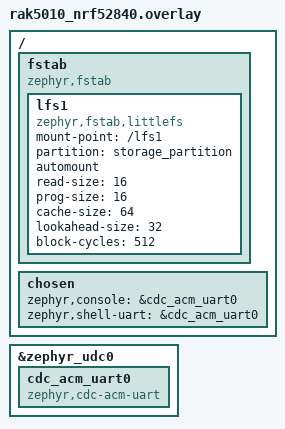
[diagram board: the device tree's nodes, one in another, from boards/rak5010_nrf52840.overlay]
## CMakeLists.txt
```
# SPDX-License-Identifier: Apache-2.0

cmake_minimum_required(VERSION 3.20.0)

find_package(Zephyr REQUIRED HINTS $ENV{ZEPHYR_BASE})
project(cert_rotation)

target_sources(app PRIVATE src/main.c)

add_custom_command(
    OUTPUT ${ZEPHYR_BINARY_DIR}/lfs.hex
    COMMAND ${PYTHON_EXECUTABLE}
      ${CMAKE_CURRENT_SOURCE_DIR}/generate-lfs-image.py
      --build-dir ${APPLICATION_BINARY_DIR}
)

add_custom_target(
    lfs ALL
    DEPENDS ${ZEPHYR_BINARY_DIR}/lfs.hex
)
```

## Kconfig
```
# Copyright (c) 2021 Golioth, Inc.
# SPDX-License-Identifier: Apache-2.0

source "${ZEPHYR_GOLIOTH_FIRMWARE_SDK_MODULE_DIR}/examples/zephyr/common/Kconfig.defconfig"

source "Kconfig.zephyr"
```

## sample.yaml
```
sample:
  description: Perform certificate rotation
  name: certificate_rotation
common:
  tags:
    - golioth
    - socket
    - goliothd
tests:
  sample.golioth.certificate_rotation:
    build_only: true
    tags:
      - golioth
      - socket
      - goliothd
    timeout: 180
    extra_configs:
      - CONFIG_GOLIOTH_SAMPLE_TWISTER_TEST=y
      - arch:posix:CONFIG_NATIVE_UART_0_ON_STDINOUT=y
    platform_allow:
      - frdm_rw612
      - native_sim
      - native_sim/native/64
      - nrf9160dk/nrf9160/ns
      - nucleo_h563zi/stm32h563xx
  sample.golioth.certificate_rotation.psa_crypto:
    build_only: true
    tags:
      - golioth
      - socket
      - goliothd
    timeout: 180
    extra_configs:
      - CONFIG_MBEDTLS_PSA_CRYPTO_C=y
      - CONFIG_GOLIOTH_SAMPLE_TWISTER_TEST=y
      - arch:posix:CONFIG_NATIVE_UART_0_ON_STDINOUT=y
      - arch:posix:CONFIG_MCUMGR_TRANSPORT_UDP_PORT=1347
    platform_allow:
      - frdm_rw612
      - native_sim
      - native_sim/native/64
      - nrf9160dk/nrf9160/ns
      - nucleo_h563zi/stm32h563xx
```

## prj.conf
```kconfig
# Application
CONFIG_GOLIOTH_SAMPLE_COMMON=y
CONFIG_LOG_BACKEND_GOLIOTH=y

# Golioth Firmware SDK with all dependencies
CONFIG_GOLIOTH_FIRMWARE_SDK=y

# Enable flash operations
CONFIG_FLASH=y
CONFIG_FLASH_MAP=y

# Enable the LittleFS file system
CONFIG_FILE_SYSTEM=y
# init before wifi credentials
CONFIG_FILE_SYSTEM_INIT_PRIORITY=89
CONFIG_FILE_SYSTEM_LITTLEFS=y
CONFIG_FILE_SYSTEM_SHELL=y
CONFIG_HEAP_MEM_POOL_SIZE=4096

# Add 256 bytes to accommodate upload command (lfs_stat overflows)
CONFIG_SYSTEM_WORKQUEUE_STACK_SIZE=2304

# Enable mcumgr
CONFIG_ZCBOR=y
CONFIG_MCUMGR=y

# Enable console with mcumgr pass through
CONFIG_CONSOLE=y
CONFIG_UART_CONSOLE=y
CONFIG_UART_CONSOLE_MCUMGR=y

# Enable the shell mcumgr transport. This allows SMP messages to pass
# through the shell to the mgmt subsystem.
CONFIG_SHELL=y
CONFIG_SHELL_BACKEND_SERIAL=y
CONFIG_BASE64=y
CONFIG_MCUMGR_TRANSPORT_SHELL=y

# Enable file system commands
CONFIG_MCUMGR_GRP_FS=y

# Enable shell commands over SMP
CONFIG_SHELL_BACKEND_DUMMY=y
CONFIG_MCUMGR_GRP_SHELL=y

# Some mgmt command handlers require a large stack.
CONFIG_MAIN_STACK_SIZE=2048

# Enable certificate authentication.
CONFIG_GOLIOTH_AUTH_METHOD_CERT=y

# Enable `log halt` and `log go` commands
CONFIG_LOG_CMDS=y

# If runtime-settings are enabled, use the file storage-backend
CONFIG_SETTINGS_FILE=y
CONFIG_SETTINGS_FILE_PATH="/lfs1/settings"

# Enable Golioth PKI Service:
CONFIG_GOLIOTH_PKI=y

# Enable MbedTLS Certificate Sigining Request writing:
CONFIG_MBEDTLS_X509_CSR_WRITE_C=y
CONFIG_MBEDTLS_PK_WRITE_C=y
CONFIG_MBEDTLS_PSA_CRYPTO_C=y
```

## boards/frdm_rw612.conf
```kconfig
CONFIG_GOLIOTH_SAMPLE_DHCP_BIND=y
CONFIG_NET_DHCPV4=y
CONFIG_BUILD_OUTPUT_HEX=y

# Ethernet autonegotiation can take longer than the default 4 s
CONFIG_PHY_AUTONEG_TIMEOUT_MS=10000

# Needed for certificate auth
CONFIG_NET_BUF_DATA_SIZE=512
CONFIG_NET_SOCKETS_CONNECT_TIMEOUT=6000
```

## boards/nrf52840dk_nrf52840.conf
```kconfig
# MCU Manager
CONFIG_MCUBOOT_BOOTUTIL_LIB=y
CONFIG_MCUMGR_MGMT_NOTIFICATION_HOOKS=y
CONFIG_MCUMGR_GRP_FS_FILE_ACCESS_HOOK=y

# Allow reboot from shell after loading certificates
CONFIG_REBOOT=y

CONFIG_NET_BUF_DATA_SIZE=256
CONFIG_NET_PKT_TX_COUNT=10

# DTLS handshake timeout
CONFIG_NET_SOCKETS_CONNECT_TIMEOUT=30000
```

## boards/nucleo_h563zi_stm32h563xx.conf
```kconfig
CONFIG_GOLIOTH_SAMPLE_DHCP_BIND=y
CONFIG_NET_DHCPV4=y

# Needed for certificate auth
CONFIG_NET_SOCKETS_CONNECT_TIMEOUT=10000
```

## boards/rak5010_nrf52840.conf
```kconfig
CONFIG_UART_ASYNC_API=y
CONFIG_MODEM_CELLULAR_APN="internet"

# USB
CONFIG_USB_DEVICE_STACK_NEXT=y
CONFIG_USBD_CDC_ACM_CLASS=y
CONFIG_CDC_ACM_SERIAL_PID=0x0004
CONFIG_CDC_ACM_SERIAL_PRODUCT_STRING="RAK5010 Zephyr"
CONFIG_CDC_ACM_SERIAL_INITIALIZE_AT_BOOT=y

CONFIG_UART_CONSOLE=y
CONFIG_UART_LINE_CTRL=y
CONFIG_LOG_BACKEND_RTT=n
CONFIG_USBD_LOG_LEVEL_OFF=y
CONFIG_USBD_CDC_ACM_LOG_LEVEL_OFF=y
CONFIG_UDC_DRIVER_LOG_LEVEL_OFF=y

# Networking
CONFIG_NETWORKING=y
CONFIG_NET_NATIVE=y
CONFIG_NET_L2_PPP=y
CONFIG_NET_IPV4=y
CONFIG_NET_UDP=y
CONFIG_NET_SOCKETS=y
CONFIG_NET_CONTEXT_RCVTIMEO=y

# DTLS handshake timeout
CONFIG_NET_SOCKETS_CONNECT_TIMEOUT=30000

# Modem driver
CONFIG_MODEM=y
CONFIG_MODEM_CELLULAR=y
CONFIG_MODEM_CMUX_WORK_BUFFER_SIZE_EXTRA=1024
```

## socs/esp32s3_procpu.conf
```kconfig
CONFIG_WIFI=y
CONFIG_HEAP_MEM_POOL_SIZE=49152
CONFIG_ESP_HEAP_MEM_POOL_REGION_1_SIZE=32768

CONFIG_NET_L2_ETHERNET=y

CONFIG_NEWLIB_LIBC=y

CONFIG_NET_DHCPV4=y

CONFIG_ESP32_WIFI_STA_AUTO_DHCPV4=y

CONFIG_NET_L2_WIFI_SHELL=y
CONFIG_GOLIOTH_SAMPLE_WIFI=y

# https://github.com/zephyrproject-rtos/zephyr/issues/63823
CONFIG_POSIX_FS=n
```

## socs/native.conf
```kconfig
# Use offloaded sockets using host BSD sockets
CONFIG_ETH_DRIVER=n
CONFIG_ETH_NATIVE_POSIX=n
CONFIG_NET_DRIVERS=y
CONFIG_NET_SOCKETS=y
CONFIG_NET_SOCKETS_OFFLOAD=y
CONFIG_NET_NATIVE_OFFLOADED_SOCKETS=y

# Use embedded libc to use Zephyr's eventfd instead of host eventfd
CONFIG_PICOLIBC=y

# Static networking
CONFIG_NET_CONFIG_LOG_LEVEL_DBG=y
CONFIG_NET_CONFIG_SETTINGS=y
CONFIG_NET_CONFIG_NEED_IPV4=y
CONFIG_NET_CONFIG_MY_IPV4_ADDR="192.0.2.1"
CONFIG_NET_CONFIG_MY_IPV4_GW="192.0.2.2"
CONFIG_NET_CONFIG_PEER_IPV4_ADDR="192.0.2.2"

# Golioth logging backend requirement
CONFIG_LOG_MODE_DEFERRED=y

# mcumgr over UDP
CONFIG_MCUMGR_TRANSPORT_SHELL=n
CONFIG_MCUMGR_TRANSPORT_UDP=y
CONFIG_MCUMGR_TRANSPORT_UDP_STACK_SIZE=2048
CONFIG_NET_SOCKETS_POLL_MAX=4
```

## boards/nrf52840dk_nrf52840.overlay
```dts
/*
 * Copyright (C) 2023 Golioth, Inc.
 *
 * SPDX-License-Identifier: Apache-2.0
 */

/ {
	fstab {
		compatible = "zephyr,fstab";

		lfs1: lfs1 {
			compatible = "zephyr,fstab,littlefs";
			mount-point = "/lfs1";
			partition = <&storage_partition>;
			automount;
			read-size = <16>;
			prog-size = <16>;
			cache-size = <64>;
			lookahead-size = <32>;
			block-cycles = <512>;
		};
	};
};
```

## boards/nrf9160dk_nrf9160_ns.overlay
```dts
/ {
	fstab {
		compatible = "zephyr,fstab";

		lfs1: lfs1 {
			compatible = "zephyr,fstab,littlefs";
			mount-point = "/lfs1";
			partition = <&storage_partition>;
			automount;
			read-size = <16>;
			prog-size = <16>;
			cache-size = <64>;
			lookahead-size = <32>;
			block-cycles = <512>;
		};
	};
};
```

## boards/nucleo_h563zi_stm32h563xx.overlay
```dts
/ {
	fstab {
		compatible = "zephyr,fstab";

		lfs1: lfs1 {
			compatible = "zephyr,fstab,littlefs";
			mount-point = "/lfs1";
			partition = <&storage_partition>;
			automount;
			read-size = <32>;
			prog-size = <32>;
			cache-size = <64>;
			lookahead-size = <32>;
			block-cycles = <512>;
		};
	};
};
```

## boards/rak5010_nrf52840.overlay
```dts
/ {
	fstab {
		compatible = "zephyr,fstab";

		lfs1: lfs1 {
			compatible = "zephyr,fstab,littlefs";
			mount-point = "/lfs1";
			partition = <&storage_partition>;
			automount;
			read-size = <16>;
			prog-size = <16>;
			cache-size = <64>;
			lookahead-size = <32>;
			block-cycles = <512>;
		};
	};

	chosen {
		zephyr,console = &cdc_acm_uart0;
		zephyr,shell-uart = &cdc_acm_uart0;
	};
};

&zephyr_udc0 {
	cdc_acm_uart0: cdc_acm_uart0 {
		compatible = "zephyr,cdc-acm-uart";
	};
};
```

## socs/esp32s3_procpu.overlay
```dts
/ {
	fstab {
		compatible = "zephyr,fstab";

		lfs1: lfs1 {
			compatible = "zephyr,fstab,littlefs";
			mount-point = "/lfs1";
			partition = <&storage_partition>;
			automount;
			read-size = <16>;
			prog-size = <16>;
			cache-size = <64>;
			lookahead-size = <32>;
			block-cycles = <512>;
		};
	};
};

&wifi {
	status = "okay";
};

&storage_partition {
	reg = <0x00250000 0x00008000>;
};
```

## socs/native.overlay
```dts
/ {
	fstab {
		compatible = "zephyr,fstab";

		lfs1: lfs1 {
			compatible = "zephyr,fstab,littlefs";
			mount-point = "/lfs1";
			partition = <&storage_partition>;
			automount;
			read-size = <16>;
			prog-size = <16>;
			cache-size = <64>;
			lookahead-size = <32>;
			block-cycles = <512>;
		};
	};
};

/delete-node/ &storage_partition;

&flash0 {
	partitions {
		storage_partition: partition@100000 {
			label = "storage";
			reg = <DT_SIZE_M(1) DT_SIZE_M(1)>;
		};
	};
};
```

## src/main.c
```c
/*
 * Copyright (c) 2025 Golioth, Inc.
 *
 * SPDX-License-Identifier: Apache-2.0
 */

#include <zephyr/logging/log.h>
LOG_MODULE_REGISTER(cert_rotation, LOG_LEVEL_DBG);

#include <golioth/client.h>
#include <golioth/pki.h>
#include <samples/common/net_connect.h>
#include <zephyr/kernel.h>
#include <zephyr/net/coap.h>
#include <zephyr/device.h>
#include <zephyr/fs/fs.h>
#include <zephyr/fs/littlefs.h>
#include <zephyr/sys/reboot.h>
#include <mbedtls/x509_csr.h>
#include <mbedtls/psa_util.h>

#define CRT_PATH "/lfs1/credentials/crt.der"
#define KEY_PATH "/lfs1/credentials/key.der"

static const uint8_t tls_ca_crt[] = {
#include "golioth-systemclient-ca_crt.inc"
};

static const uint8_t tls_secondary_ca_crt[] = {
#if CONFIG_GOLIOTH_SECONDARY_CA_CRT
#include "golioth-systemclient-secondary_ca_crt.inc"
#endif
};

#define CSR_BUF_SIZE 300

struct golioth_client *client;
static K_SEM_DEFINE(connected, 0, 1);

static struct
{
    struct k_sem valid;
    uint8_t *buf;
    size_t len;
} new_cert;

static void on_client_event(struct golioth_client *client,
                            enum golioth_client_event event,
                            void *arg)
{
    bool is_connected = (event == GOLIOTH_CLIENT_EVENT_CONNECTED);
    if (is_connected)
    {
        k_sem_give(&connected);
    }

    LOG_INF("Golioth client %s", is_connected ? "connected" : "disconnected");
}

static int load_credential_from_fs(const char *path, uint8_t **buf_p, size_t *buf_len)
{
    struct fs_file_t file;
    struct fs_dirent dirent;

    fs_file_t_init(&file);

    int err = fs_stat(path, &dirent);

    if (err < 0)
    {
        LOG_WRN("Could not stat %s, err: %d", path, err);
        goto finish;
    }
    if (dirent.type != FS_DIR_ENTRY_FILE)
    {
        LOG_ERR("%s is not a file", path);
        err = -EISDIR;
        goto finish;
    }
    if (dirent.size == 0)
    {
        LOG_ERR("%s is an empty file", path);
        err = -EINVAL;
        goto finish;
    }


    err = fs_open(&file, path, FS_O_READ);

    if (err < 0)
    {
        LOG_ERR("Could not open %s", path);
        goto finish;
    }

    /* NOTE: *buf_p is used directly by the TLS Credentials library, and so must remain
     * allocated for the lifetime of the session.
     */

    free(*buf_p);
    *buf_p = malloc(dirent.size);

    if (*buf_p == NULL)
    {
        LOG_ERR("Could not allocate space to read credential");
        err = -ENOMEM;
        goto finish_with_file;
    }

    err = fs_read(&file, *buf_p, dirent.size);
    if (err < 0)
    {
        LOG_ERR("Could not read %s, err: %d", path, err);
        free(*buf_p);
        goto finish_with_file;
    }

    LOG_INF("Read %d bytes from %s", dirent.size, path);

    /* Set the size of the allocated buffer */
    *buf_len = dirent.size;

finish_with_file:
    fs_close(&file);

finish:
    return err;
}

static void recv_cert(struct golioth_client *client,
                      enum golioth_status status,
                      const struct golioth_coap_rsp_code *coap_rsp_code,
                      const char *path,
                      const uint8_t *payload,
                      size_t payload_size,
                      void *arg)
{
    if (status != GOLIOTH_OK)
    {
        LOG_ERR("Request failed: %d (CoAP status %d.%02d)",
                status,
                coap_rsp_code->code_class,
                coap_rsp_code->code_detail);
        return;
    }

    // Got a signed certificate based on our Certificate Signing Request:
    new_cert.buf = malloc(payload_size);
    if (new_cert.buf == NULL)
    {
        LOG_ERR("Failed to allocate memory for new certificate");
        return;
    }

    memcpy(new_cert.buf, payload, payload_size);
    new_cert.len = payload_size;

    k_sem_give(&new_cert.valid);
}

static int start_certificate_rotation(const uint8_t *csr, size_t size)
{
    k_sem_init(&new_cert.valid, 0, 1);

    return golioth_pki_issue_cert(client, csr, size, recv_cert, CRT_PATH);
}

static uint8_t *create_csr(const uint8_t *pkey, size_t pkey_len, size_t *len)
{
    int err;
    /* Import the key pair into an mbedtls pk context. This API also supports pulling
     * the key from the PSA storage.
     */
    struct mbedtls_pk_context pk;
    mbedtls_pk_init(&pk);

    err = mbedtls_pk_parse_key(&pk,
                               pkey,
                               pkey_len,
                               NULL,
                               0,
                               mbedtls_psa_get_random,
                               MBEDTLS_PSA_RANDOM_STATE);
    if (err)
    {
        LOG_ERR("Unable to parse key: %d", err);
        return NULL;
    }

    // Create a Certificate Signing Request:
    struct mbedtls_x509write_csr csr;
    mbedtls_x509write_csr_init(&csr);

    mbedtls_x509write_csr_set_key(&csr, &pk);
    mbedtls_x509write_csr_set_md_alg(&csr, MBEDTLS_MD_SHA256);

    uint8_t *der = malloc(CSR_BUF_SIZE);
    if (der == NULL)
    {
        LOG_ERR("Failed to allocate memory for csr");
        return NULL;
    }

    // The API requires a DER formatted version of the CSR:
    int res = mbedtls_x509write_csr_der(&csr,
                                        der,
                                        CSR_BUF_SIZE,
                                        mbedtls_psa_get_random,
                                        MBEDTLS_PSA_RANDOM_STATE);
    if (res < 0)
    {
        LOG_ERR("Failed to write CSR to DER: %#x", -res);
        mbedtls_x509write_csr_free(&csr);
        mbedtls_pk_free(&pk);
        free(der);
        return NULL;
    }

    *len = res;
    mbedtls_x509write_csr_free(&csr);
    mbedtls_pk_free(&pk);

    // The csr is written at the end of the available buffer, so we need to return with an offset:
    return &der[CSR_BUF_SIZE - res];
}

int main(void)
{
    LOG_DBG("Start certificate rotation sample");

    net_connect();

    uint8_t *tls_client_crt = NULL;
    uint8_t *tls_client_key = NULL;
    size_t tls_client_crt_len, tls_client_key_len;

    while (1)
    {
        int ret = load_credential_from_fs(CRT_PATH, &tls_client_crt, &tls_client_crt_len);
        if (ret > 0)
        {
            ret = load_credential_from_fs(KEY_PATH, &tls_client_key, &tls_client_key_len);
            if (ret > 0)
            {
                break;
            }
        }

        k_sleep(K_SECONDS(5));
    }

    if (tls_client_crt == NULL || tls_client_key == NULL)
    {
        LOG_ERR("Error reading certificate credentials from filesystem");
        return 0;
    }

    struct golioth_client_config client_config = {
        .credentials =
            {
                .auth_type = GOLIOTH_TLS_AUTH_TYPE_PKI,
                .pki =
                    {
                        .ca_cert = tls_ca_crt,
                        .ca_cert_len = sizeof(tls_ca_crt),
                        .public_cert = tls_client_crt,
                        .public_cert_len = tls_client_crt_len,
                        .private_key = tls_client_key,
                        .private_key_len = tls_client_key_len,
                        .secondary_ca_cert = tls_secondary_ca_crt,
                        .secondary_ca_cert_len = sizeof(tls_secondary_ca_crt),
                    },
            },
    };

    client = golioth_client_create(&client_config);

    golioth_client_register_event_callback(client, on_client_event, NULL);

    k_sem_take(&connected, K_FOREVER);

    /**
     * Rotate the certificate by submitting a Certificate Signing Request to Golioth.
     * The CSR does not have to contain the project or device ID, as this will be
     * inferred from the current credentials in the Golioth backend.
     */
    size_t csr_size = 0;
    uint8_t *csr = create_csr(tls_client_key, tls_client_key_len, &csr_size);
    if (csr == NULL)
    {
        return 0;
    }

    int err = start_certificate_rotation(csr, csr_size);
    if (err)
    {
        LOG_ERR("Certificate rotation failed: %d", err);
        free(csr);
        return 0;
    }

    k_sem_take(&new_cert.valid, K_FOREVER);
    free(csr);

    LOG_INF("Received new certificate. Reconnecting...");

    golioth_client_destroy(client);

    // We no longer need the old certificate:
    free(tls_client_crt);
    tls_client_crt = NULL;

    // Use the new certificate:
    client_config.credentials.pki.public_cert = new_cert.buf;
    client_config.credentials.pki.public_cert_len = new_cert.len;

    // Reconnect:
    k_sem_init(&connected, 0, 1);
    client = golioth_client_create(&client_config);
    if (client == NULL)
    {
        LOG_ERR("Failed to create new golioth client");
        return 0;
    }

    golioth_client_register_event_callback(client, on_client_event, NULL);

    k_sem_take(&connected, K_FOREVER);

    LOG_INF("Reconnected.");

    while (true)
    {
        LOG_INF("Sending with new certificate");
        k_sleep(K_SECONDS(5));
    }

    return 0;
}
```
